# tviic2d6m register map
Vendor: Infineon Technologies; Series: TVIIC2D6M; File version: 1.0
CPU: CM7 r0p1, little endian, MPU, FPU, double-precision FPU, I-cache, D-cache, VTOR, ITCM, DTCM, 3 interrupt priority bits, 16 interrupts
Registers are 32-bit, read-write, reset 0x0 unless marked. A register's access mark holds for its fields unless they carry their own. Offsets are from the block's base; [hi:lo] are bit positions; lines under a group give offsets from that group; {n}, {i} and the like mark numbered series.

## SMIF0 (part 1 of 3) — SMIF subsystem (bridge + 2 core SMIFs, OR no bridge and 1 core SMIF)
Base 0x40400000
0x00 SMIF_BRIDGE group — AXI/AHB interleaving and FOTA bridge
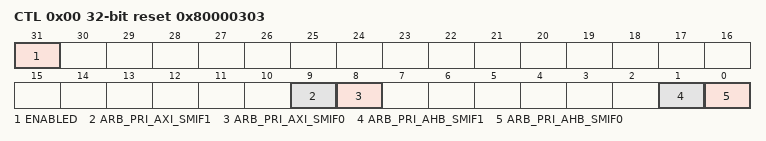
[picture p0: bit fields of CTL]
  0x00 CTL reset 0x80000303 — Global control registers for the bridge
    [31] ENABLED — Determines whether the bridge is enabled or not: 0: Remapping bridge is disabled and bypassed. In that case the SMIF0 XIP region connects directly to the SMIF0 physical space, and the SMIF1 XIP region maps directly to the SMIF1 physical space. As such no extra latency or arbitration cycles are incurred. All remap region registers are ignored as are the ARB_PRI_* registers. 1: Remapping bridge is invoked which allows for the remap regions to be employed. However, an extra bus cycle of latency is incurred on all AHB and AXI address channel accesses to allow for remap calculations. Also there can be arbitration latency in the case where 2 masters are trying to access a single physical SMIF. This bit should not be changed if there is any ongoing or pending XIP activity. When this bit is 1, it is forbidden to change any bridge configuration registers (i.e., the rest of the bits in this CTL register and any bits in the REMAP_REGION registers).
    [9] ARB_PRI_AXI_SMIF1 — Same as ARB_PRI_AHB_SMIF0 except for two AXI masters accessing the physical SMIF1 space.
    [8] ARB_PRI_AXI_SMIF0 — Same as ARB_PRI_AHB_SMIF0 except for two AXI masters accessing the physical SMIF0 space.
    [1] ARB_PRI_AHB_SMIF1 — Same as ARB_PRI_AHB_SMIF0 except for accessing the physical SMIF1 space.
    [0] ARB_PRI_AHB_SMIF0 — If two AHB masters are both trying to access the physical SMIF0 space from the separate SMIF0 and SMIF1 XIP spaces as allowed through remap regions, the winner is determined by this bit: 0: the master accessing through the SMIF0 XIP space 1: the master accessing through the SMIF1 XIP space
  {0x1000+0x100*j} SMIF_REMAP_REGION[{j}] (j=0..7) group — 'Remap regions' which define how XIP accesses can be remapped into SMIF physical spaces
    0x00 CTL reset 0x30000 — Control bits for remap region
      [31] SMIF_SPACE — Determines which SMIF XIP space the ADDR register applies to: 0: SMIF0 1: SMIF1
      [18:16] INTLV_STEP_SIZE — Interleaving step size (only relevant when USE_SMIF=3): 0: 8 bytes 1: 16 bytes 2: 32 bytes 3: 64 bytes 4: 128 bytes
      [1:0] USE_SMIF — Determines whether the remap region is active or not, and if active whether it is a simple remap or interleaving remap: 0: remap region is inactive (all other registers associated with this remap region are ignored) 1: remap accesses to SMIF0 2: remap accesses to SMIF1 3: remap accesses to SMIF0 and SMIF1 on an interleaving basis This and all other remap region registers are relevant only if the bridge's CTL.ENABLED=1.
    0x10 ADDR — Base address of remap region
      [28:20] ADDR — Determines the base address within a SMIF XIP space of a remap region. CTL.SMIF_SPACE determines which SMIF XIP space this address exists in. The associated MASK register determines the size of the remap region. The base address must be situated on a boundary that equals the size of the remap region. If remap regions overlap then the lower numbered remap region will be used where there is overlap.
    0x14 MASK — Mask value to be paired with ADDR
      [28:20] MASK — Determines the size of the remap region in the XIP space. Pairs with ADDR. To program, determine the size of the region (range is 1MB to 512MB) then set the bits 'above' that value to 1 and the lower bits to 0. Some examples: 1MB: 0x1FF 2MB: 0x1FE 4MB: 0x1FC ... 256MB: 0x100 512MB: 0x000 If USE_SMIF=11 (interleaving) then MASK=0x1FF is illegal.
    0x18 SMIF0_REMAP — Base address for remaps into SMIF0 physical memory space
      [28:20] SMIF0_REMAP — Determines the base address within the SMIF0 physical space where remaps to SMIF0 are to be located. The size of the remap region is equal to MASK, unless interleaving is true (CTL.USE_SMIF=3) then it is equal to half the size of MASK. SMIF0_REMAP must be situated on a boundardy that equals that resulting granularity.
    0x1C SMIF1_REMAP — Base address for remaps into SMIF1 physical memory space
      [28:20] SMIF1_REMAP — Same as described in SMIF0_REMAP except for SMIF1.
